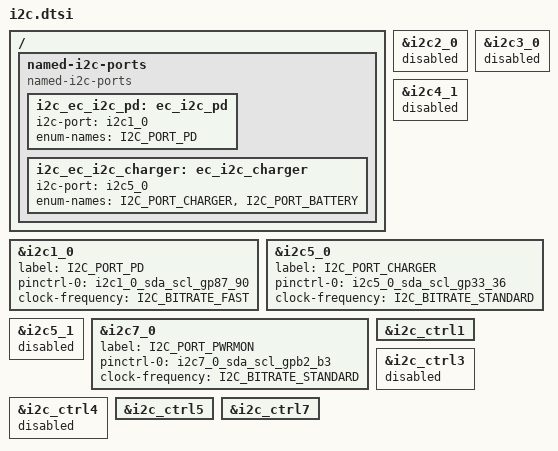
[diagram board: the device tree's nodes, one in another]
/* Copyright 2026 The ChromiumOS Authors
 * Use of this source code is governed by a BSD-style license that can be
 * found in the LICENSE file.
 */

/ {
	named-i2c-ports {
		compatible = "named-i2c-ports";

		i2c_ec_i2c_pd: ec_i2c_pd {
			i2c-port = <&i2c1_0>;
			enum-names = "I2C_PORT_PD";
		};
		i2c_ec_i2c_charger: ec_i2c_charger {
			i2c-port = <&i2c5_0>;
			enum-names = "I2C_PORT_CHARGER",
				"I2C_PORT_BATTERY";
		};
	};
};

&i2c1_0 {
	label = "I2C_PORT_PD";
	status = "okay";
	pinctrl-0 = <&i2c1_0_sda_scl_gp87_90>;
	pinctrl-names = "default";
	clock-frequency = <I2C_BITRATE_FAST>;
};

&i2c2_0 {
	status = "disabled";
};

&i2c3_0 {
	status = "disabled";
};

&i2c4_1 {
	status = "disabled";
};

&i2c5_0 {
	label = "I2C_PORT_CHARGER";
	status = "okay";
	pinctrl-0 = <&i2c5_0_sda_scl_gp33_36>;
	pinctrl-names = "default";
	clock-frequency = <I2C_BITRATE_STANDARD>;
};

&i2c5_1 {
	status = "disabled";
};

&i2c7_0 {
	label = "I2C_PORT_PWRMON";
	status = "okay";
	pinctrl-0 = <&i2c7_0_sda_scl_gpb2_b3>;
	pinctrl-names = "default";
	clock-frequency = <I2C_BITRATE_STANDARD>;
};

&i2c_ctrl1 {
	status = "okay";
};

&i2c_ctrl3 {
	status = "disabled";
};

&i2c_ctrl4 {
	status = "disabled";
};

&i2c_ctrl5 {
	status = "okay";
};

&i2c_ctrl7 {
	status = "okay";
};
